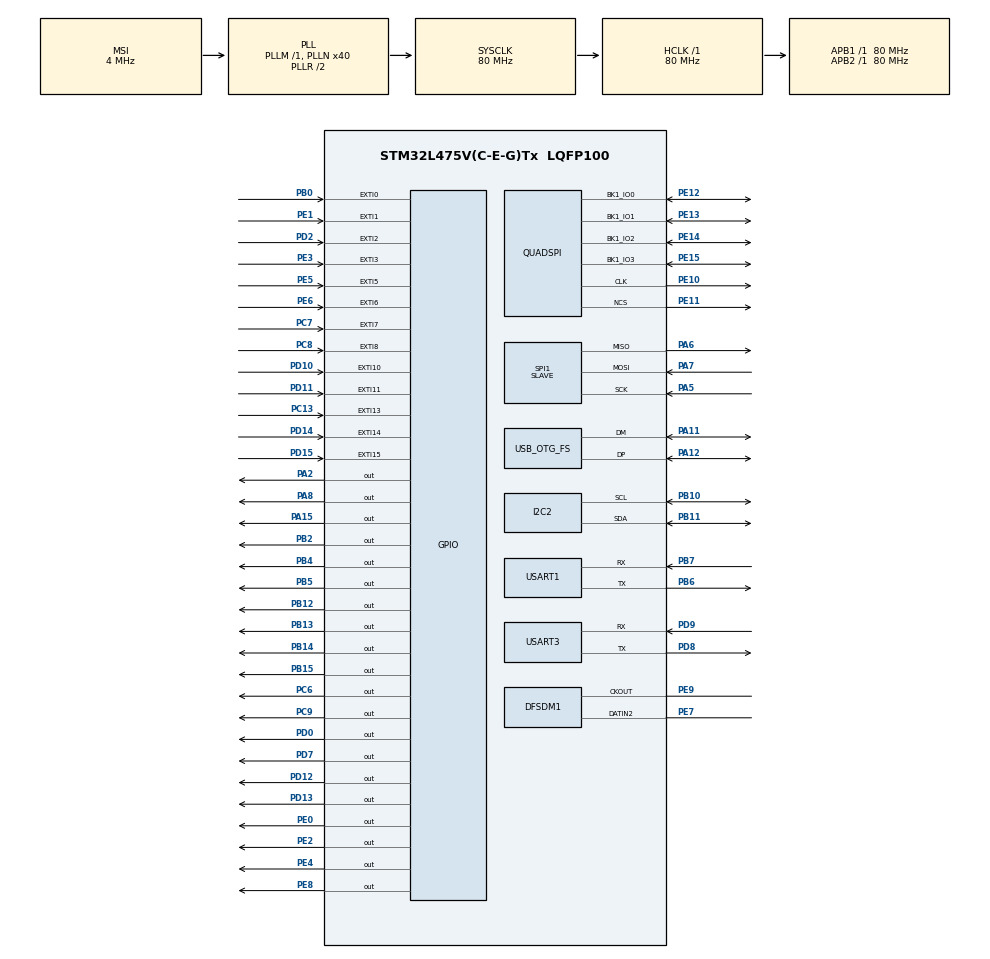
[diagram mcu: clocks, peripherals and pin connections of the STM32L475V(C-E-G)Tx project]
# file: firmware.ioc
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FREERTOS.Tasks01=defaultTask,0,128,StartDefaultTask,Default,NULL
Mcu.Family=STM32L4
Mcu.Name=STM32L475V(C-E-G)Tx
Mcu.Package=LQFP100
NVIC.EXTI15_10_IRQn=true\:5\:0\:false\:false\:true\:true\:true
NVIC.EXTI9_5_IRQn=true\:5\:0\:false\:false\:true\:true\:true
NVIC.PriorityGroup=NVIC_PRIORITYGROUP_4
NVIC.SPI1_IRQn=true\:5\:0\:false\:false\:true\:true\:true
NVIC.TIM1_UP_TIM16_IRQn=true\:0\:0\:false\:false\:true\:false\:false
NVIC.TimeBase=TIM1_UP_TIM16_IRQn
NVIC.TimeBaseIP=TIM1
PA0.GPIO_ModeDefaultPP=GPIO_MODE_AF_PP
PA0.GPIO_PuPd=GPIO_NOPULL
PA0.GPIO_Speed=GPIO_SPEED_FREQ_VERY_HIGH
PA0.Signal=UART4_TX
PA1.GPIO_ModeDefaultPP=GPIO_MODE_AF_PP
PA1.GPIO_PuPd=GPIO_NOPULL
PA1.GPIO_Speed=GPIO_SPEED_FREQ_VERY_HIGH
PA1.Signal=UART4_RX
PA10.GPIO_Mode=GPIO_MODE_AF_PP
PA10.GPIO_PuPd=GPIO_NOPULL
PA10.GPIO_Speed=GPIO_SPEED_FREQ_VERY_HIGH
PA10.Signal=USB_OTG_FS_ID
PA11.GPIO_Mode=GPIO_MODE_AF_PP
PA11.GPIO_PuPd=GPIO_NOPULL
PA11.GPIO_Speed=GPIO_SPEED_FREQ_VERY_HIGH
PA11.Mode=Device_Only
PA11.Signal=USB_OTG_FS_DM
PA12.GPIO_Mode=GPIO_MODE_AF_PP
PA12.GPIO_PuPd=GPIO_NOPULL
PA12.GPIO_Speed=GPIO_SPEED_FREQ_VERY_HIGH
PA12.Mode=Device_Only
PA12.Signal=USB_OTG_FS_DP
PA13\ (JTMS-SWDIO).Mode=Serial_Wire
PA13\ (JTMS-SWDIO).Signal=SYS_JTMS-SWDIO
PA14\ (JTCK-SWCLK).Mode=Serial_Wire
PA14\ (JTCK-SWCLK).Signal=SYS_JTCK-SWCLK
PA15\ (JTDI).GPIO_ModeDefaultOutputPP=GPIO_MODE_OUTPUT_PP
PA15\ (JTDI).GPIO_PuPd=GPIO_NOPULL
PA15\ (JTDI).GPIO_Speed=GPIO_SPEED_FREQ_LOW
PA15\ (JTDI).PinState=GPIO_PIN_RESET
PA15\ (JTDI).Signal=GPIO_Output
PA2.GPIO_ModeDefaultOutputPP=GPIO_MODE_OUTPUT_PP
PA2.GPIO_PuPd=GPIO_NOPULL
PA2.GPIO_Speed=GPIO_SPEED_FREQ_LOW
PA2.PinState=GPIO_PIN_RESET
PA2.Signal=GPIO_Output
PA3.GPIO_ModeDefaultPP=GPIO_MODE_AF_PP
PA3.GPIO_PuPd=GPIO_NOPULL
PA3.GPIO_Speed=GPIO_SPEED_FREQ_LOW
PA3.Signal=S_TIM2_CH4
PA4.GPIO_Mode=GPIO_MODE_ANALOG_ADC_CONTROL
PA4.GPIO_PuPd=GPIO_NOPULL
PA4.Signal=ADCx_IN9
PA5.GPIO_Mode=GPIO_MODE_AF_PP
PA5.GPIO_PuPd=GPIO_NOPULL
PA5.GPIO_Speed=GPIO_SPEED_FREQ_VERY_HIGH
PA5.Mode=Full_Duplex_Slave
PA5.Signal=SPI1_SCK
PA6.GPIO_Mode=GPIO_MODE_AF_PP
PA6.GPIO_PuPd=GPIO_NOPULL
PA6.GPIO_Speed=GPIO_SPEED_FREQ_VERY_HIGH
PA6.Mode=Full_Duplex_Slave
PA6.Signal=SPI1_MISO
PA7.GPIO_Mode=GPIO_MODE_AF_PP
PA7.GPIO_PuPd=GPIO_NOPULL
PA7.GPIO_Speed=GPIO_SPEED_FREQ_VERY_HIGH
PA7.Mode=Full_Duplex_Slave
PA7.Signal=SPI1_MOSI
PA8.GPIO_ModeDefaultOutputPP=GPIO_MODE_OUTPUT_PP
PA8.GPIO_PuPd=GPIO_NOPULL
PA8.GPIO_Speed=GPIO_SPEED_FREQ_LOW
PA8.PinState=GPIO_PIN_RESET
PA8.Signal=GPIO_Output
PA9.GPIO_Mode=GPIO_MODE_INPUT
PA9.GPIO_PuPd=GPIO_NOPULL
PA9.Signal=USB_OTG_FS_VBUS
PB0.GPIO_ModeDefaultEXTI=GPIO_MODE_IT_RISING
PB0.GPIO_PuPd=GPIO_NOPULL
PB0.Signal=GPXTI0
PB1.GPIO_Mode=GPIO_MODE_ANALOG_ADC_CONTROL
PB1.GPIO_PuPd=GPIO_NOPULL
PB1.Signal=ADCx_IN16
PB10.GPIO_Mode=GPIO_MODE_AF_OD
PB10.GPIO_PuPdOD=GPIO_PULLUP
PB10.GPIO_Speed=GPIO_SPEED_FREQ_VERY_HIGH
PB10.Mode=I2C
PB10.Signal=I2C2_SCL
PB11.GPIO_Mode=GPIO_MODE_AF_OD
PB11.GPIO_PuPdOD=GPIO_PULLUP
PB11.GPIO_Speed=GPIO_SPEED_FREQ_VERY_HIGH
PB11.Mode=I2C
PB11.Signal=I2C2_SDA
PB12.GPIO_ModeDefaultOutputPP=GPIO_MODE_OUTPUT_PP
PB12.GPIO_PuPd=GPIO_NOPULL
PB12.GPIO_Speed=GPIO_SPEED_FREQ_LOW
PB12.PinState=GPIO_PIN_RESET
PB12.Signal=GPIO_Output
PB13.GPIO_ModeDefaultOutputPP=GPIO_MODE_OUTPUT_PP
PB13.GPIO_PuPd=GPIO_NOPULL
PB13.GPIO_Speed=GPIO_SPEED_FREQ_LOW
PB13.PinState=GPIO_PIN_RESET
PB13.Signal=GPIO_Output
PB14.GPIO_ModeDefaultOutputPP=GPIO_MODE_OUTPUT_PP
PB14.GPIO_PuPd=GPIO_NOPULL
PB14.GPIO_Speed=GPIO_SPEED_FREQ_LOW
PB14.PinState=GPIO_PIN_RESET
PB14.Signal=GPIO_Output
PB15.GPIO_ModeDefaultOutputPP=GPIO_MODE_OUTPUT_PP
PB15.GPIO_PuPd=GPIO_NOPULL
PB15.GPIO_Speed=GPIO_SPEED_FREQ_LOW
PB15.PinState=GPIO_PIN_RESET
PB15.Signal=GPIO_Output
PB2.GPIO_ModeDefaultOutputPP=GPIO_MODE_OUTPUT_PP
PB2.GPIO_PuPd=GPIO_NOPULL
PB2.GPIO_Speed=GPIO_SPEED_FREQ_LOW
PB2.PinState=GPIO_PIN_RESET
PB2.Signal=GPIO_Output
PB3\ (JTDO-TRACESWO).Signal=SYS_JTDO-SWO
PB4\ (NJTRST).GPIO_ModeDefaultOutputPP=GPIO_MODE_OUTPUT_PP
PB4\ (NJTRST).GPIO_PuPd=GPIO_NOPULL
PB4\ (NJTRST).GPIO_Speed=GPIO_SPEED_FREQ_LOW
PB4\ (NJTRST).PinState=GPIO_PIN_RESET
PB4\ (NJTRST).Signal=GPIO_Output
PB5.GPIO_ModeDefaultOutputPP=GPIO_MODE_OUTPUT_PP
PB5.GPIO_PuPd=GPIO_NOPULL
PB5.GPIO_Speed=GPIO_SPEED_FREQ_LOW
PB5.PinState=GPIO_PIN_RESET
PB5.Signal=GPIO_Output
PB6.GPIO_FM6=__NULL
PB6.GPIO_ModeDefaultPP=GPIO_MODE_AF_PP
PB6.GPIO_PuPd=GPIO_NOPULL
PB6.GPIO_Speed=GPIO_SPEED_FREQ_VERY_HIGH
PB6.Mode=Asynchronous
PB6.Signal=USART1_TX
PB7.GPIO_FM7=__NULL
PB7.GPIO_ModeDefaultPP=GPIO_MODE_AF_PP
PB7.GPIO_PuPd=GPIO_NOPULL
PB7.GPIO_Speed=GPIO_SPEED_FREQ_VERY_HIGH
PB7.Mode=Asynchronous
PB7.Signal=USART1_RX
PB8.GPIO_FM8=__NULL
PB8.GPIO_Mode=GPIO_MODE_AF_OD
PB8.GPIO_PuPdOD=GPIO_PULLUP
PB8.GPIO_Speed=GPIO_SPEED_FREQ_VERY_HIGH
PB8.Signal=I2C1_SCL
PB9.GPIO_FM9=__NULL
PB9.GPIO_Mode=GPIO_MODE_AF_OD
PB9.GPIO_PuPdOD=GPIO_PULLUP
PB9.GPIO_Speed=GPIO_SPEED_FREQ_VERY_HIGH
PB9.Signal=I2C1_SDA
PC0.GPIO_Mode=GPIO_MODE_ANALOG_ADC_CONTROL
PC0.GPIO_PuPd=GPIO_NOPULL
PC0.Signal=ADCx_IN1
PC1.GPIO_Mode=GPIO_MODE_ANALOG_ADC_CONTROL
PC1.GPIO_PuPd=GPIO_NOPULL
PC1.Signal=ADCx_IN2
PC10.GPIO_Mode=GPIO_MODE_AF_PP
PC10.GPIO_PuPd=GPIO_NOPULL
PC10.GPIO_Speed=GPIO_SPEED_FREQ_VERY_HIGH
PC10.Signal=SPI3_SCK
PC11.GPIO_Mode=GPIO_MODE_AF_PP
PC11.GPIO_PuPd=GPIO_NOPULL
PC11.GPIO_Speed=GPIO_SPEED_FREQ_VERY_HIGH
PC11.Signal=SPI3_MISO
PC12.GPIO_Mode=GPIO_MODE_AF_PP
PC12.GPIO_PuPd=GPIO_NOPULL
PC12.GPIO_Speed=GPIO_SPEED_FREQ_VERY_HIGH
PC12.Signal=SPI3_MOSI
PC13.GPIO_ModeDefaultEXTI=GPIO_MODE_IT_RISING
PC13.GPIO_PuPd=GPIO_NOPULL
PC13.Signal=GPXTI13
PC14-OSC32_IN\ (PC14).Mode=LSE-External-Oscillator
PC14-OSC32_IN\ (PC14).Signal=RCC_OSC32_IN
PC15-OSC32_OUT\ (PC15).Mode=LSE-External-Oscillator
PC15-OSC32_OUT\ (PC15).Signal=RCC_OSC32_OUT
PC2.GPIO_Mode=GPIO_MODE_ANALOG_ADC_CONTROL
PC2.GPIO_PuPd=GPIO_NOPULL
PC2.Signal=ADCx_IN3
PC3.GPIO_Mode=GPIO_MODE_ANALOG_ADC_CONTROL
PC3.GPIO_PuPd=GPIO_NOPULL
PC3.Signal=ADCx_IN4
PC4.GPIO_Mode=GPIO_MODE_ANALOG_ADC_CONTROL
PC4.GPIO_PuPd=GPIO_NOPULL
PC4.Signal=ADCx_IN13
PC5.GPIO_Mode=GPIO_MODE_ANALOG_ADC_CONTROL
PC5.GPIO_PuPd=GPIO_NOPULL
PC5.Signal=ADCx_IN14
PC6.GPIO_ModeDefaultOutputPP=GPIO_MODE_OUTPUT_PP
PC6.GPIO_PuPd=GPIO_NOPULL
PC6.GPIO_Speed=GPIO_SPEED_FREQ_LOW
PC6.PinState=GPIO_PIN_RESET
PC6.Signal=GPIO_Output
PC7.GPIO_ModeDefaultEXTI=GPIO_MODE_IT_RISING
PC7.GPIO_PuPd=GPIO_NOPULL
PC7.Signal=GPXTI7
PC8.GPIO_ModeDefaultEXTI=GPIO_MODE_IT_RISING
PC8.GPIO_PuPd=GPIO_NOPULL
PC8.Signal=GPXTI8
PC9.GPIO_ModeDefaultOutputPP=GPIO_MODE_OUTPUT_PP
PC9.GPIO_PuPd=GPIO_NOPULL
PC9.GPIO_Speed=GPIO_SPEED_FREQ_LOW
PC9.PinState=GPIO_PIN_RESET
PC9.Signal=GPIO_Output
PD0.GPIO_ModeDefaultOutputPP=GPIO_MODE_OUTPUT_PP
PD0.GPIO_PuPd=GPIO_NOPULL
PD0.GPIO_Speed=GPIO_SPEED_FREQ_LOW
PD0.PinState=GPIO_PIN_RESET
PD0.Signal=GPIO_Output
PD1.GPIO_Mode=GPIO_MODE_AF_PP
PD1.GPIO_PuPd=GPIO_NOPULL
PD1.GPIO_Speed=GPIO_SPEED_FREQ_VERY_HIGH
PD1.Signal=SPI2_SCK
PD10.GPIO_ModeDefaultEXTI=GPIO_MODE_IT_RISING
PD10.GPIO_PuPd=GPIO_NOPULL
PD10.Signal=GPXTI10
PD11.GPIO_ModeDefaultEXTI=GPIO_MODE_IT_RISING
PD11.GPIO_PuPd=GPIO_NOPULL
PD11.Signal=GPXTI11
PD12.GPIO_ModeDefaultOutputPP=GPIO_MODE_OUTPUT_PP
PD12.GPIO_PuPd=GPIO_NOPULL
PD12.GPIO_Speed=GPIO_SPEED_FREQ_LOW
PD12.PinState=GPIO_PIN_RESET
PD12.Signal=GPIO_Output
PD13.GPIO_ModeDefaultOutputPP=GPIO_MODE_OUTPUT_PP
PD13.GPIO_PuPd=GPIO_NOPULL
PD13.GPIO_Speed=GPIO_SPEED_FREQ_LOW
PD13.PinState=GPIO_PIN_RESET
PD13.Signal=GPIO_Output
PD14.GPIO_ModeDefaultEXTI=GPIO_MODE_IT_RISING
PD14.GPIO_PuPd=GPIO_NOPULL
PD14.Signal=GPXTI14
PD15.GPIO_ModeDefaultEXTI=GPIO_MODE_IT_RISING
PD15.GPIO_PuPd=GPIO_NOPULL
PD15.Signal=GPXTI15
PD2.GPIO_ModeDefaultEXTI=GPIO_MODE_IT_RISING
PD2.GPIO_PuPd=GPIO_NOPULL
PD2.Signal=GPXTI2
PD3.GPIO_Mode=GPIO_MODE_AF_PP
PD3.GPIO_PuPd=GPIO_NOPULL
PD3.GPIO_Speed=GPIO_SPEED_FREQ_VERY_HIGH
PD3.Signal=USART2_CTS
PD4.GPIO_Mode=GPIO_MODE_AF_PP
PD4.GPIO_PuPd=GPIO_NOPULL
PD4.GPIO_Speed=GPIO_SPEED_FREQ_VERY_HIGH
PD4.Signal=USART2_RTS
PD5.GPIO_ModeDefaultPP=GPIO_MODE_AF_PP
PD5.GPIO_PuPd=GPIO_NOPULL
PD5.GPIO_Speed=GPIO_SPEED_FREQ_VERY_HIGH
PD5.Signal=USART2_TX
PD6.GPIO_ModeDefaultPP=GPIO_MODE_AF_PP
PD6.GPIO_PuPd=GPIO_NOPULL
PD6.GPIO_Speed=GPIO_SPEED_FREQ_VERY_HIGH
PD6.Signal=USART2_RX
PD7.GPIO_ModeDefaultOutputPP=GPIO_MODE_OUTPUT_PP
PD7.GPIO_PuPd=GPIO_NOPULL
PD7.GPIO_Speed=GPIO_SPEED_FREQ_LOW
PD7.PinState=GPIO_PIN_RESET
PD7.Signal=GPIO_Output
PD8.GPIO_ModeDefaultPP=GPIO_MODE_AF_PP
PD8.GPIO_PuPd=GPIO_NOPULL
PD8.GPIO_Speed=GPIO_SPEED_FREQ_VERY_HIGH
PD8.Mode=Asynchronous
PD8.Signal=USART3_TX
PD9.GPIO_ModeDefaultPP=GPIO_MODE_AF_PP
PD9.GPIO_PuPd=GPIO_NOPULL
PD9.GPIO_Speed=GPIO_SPEED_FREQ_VERY_HIGH
PD9.Mode=Asynchronous
PD9.Signal=USART3_RX
PE0.GPIO_ModeDefaultOutputPP=GPIO_MODE_OUTPUT_PP
PE0.GPIO_PuPd=GPIO_NOPULL
PE0.GPIO_Speed=GPIO_SPEED_FREQ_LOW
PE0.PinState=GPIO_PIN_RESET
PE0.Signal=GPIO_Output
PE1.GPIO_ModeDefaultEXTI=GPIO_MODE_IT_RISING
PE1.GPIO_PuPd=GPIO_NOPULL
PE1.Signal=GPXTI1
PE10.GPIO_Mode=GPIO_MODE_AF_PP
PE10.GPIO_PuPd=GPIO_NOPULL
PE10.GPIO_Speed=GPIO_SPEED_FREQ_VERY_HIGH
PE10.Mode=Single Bank
PE10.Signal=QUADSPI_CLK
PE11.GPIO_Mode=GPIO_MODE_AF_PP
PE11.GPIO_PuPd=GPIO_NOPULL
PE11.GPIO_Speed=GPIO_SPEED_FREQ_VERY_HIGH
PE11.Mode=Single Bank
PE11.Signal=QUADSPI_NCS
PE12.GPIO_Mode=GPIO_MODE_AF_PP
PE12.GPIO_PuPd=GPIO_NOPULL
PE12.GPIO_Speed=GPIO_SPEED_FREQ_VERY_HIGH
PE12.Mode=Single Bank
PE12.Signal=QUADSPI_BK1_IO0
PE13.GPIO_Mode=GPIO_MODE_AF_PP
PE13.GPIO_PuPd=GPIO_NOPULL
PE13.GPIO_Speed=GPIO_SPEED_FREQ_VERY_HIGH
PE13.Mode=Single Bank
PE13.Signal=QUADSPI_BK1_IO1
PE14.GPIO_Mode=GPIO_MODE_AF_PP
PE14.GPIO_PuPd=GPIO_NOPULL
PE14.GPIO_Speed=GPIO_SPEED_FREQ_VERY_HIGH
PE14.Mode=Single Bank
PE14.Signal=QUADSPI_BK1_IO2
PE15.GPIO_Mode=GPIO_MODE_AF_PP
PE15.GPIO_PuPd=GPIO_NOPULL
PE15.GPIO_Speed=GPIO_SPEED_FREQ_VERY_HIGH
PE15.Mode=Single Bank
PE15.Signal=QUADSPI_BK1_IO3
PE2.GPIO_ModeDefaultOutputPP=GPIO_MODE_OUTPUT_PP
PE2.GPIO_PuPd=GPIO_NOPULL
PE2.GPIO_Speed=GPIO_SPEED_FREQ_LOW
PE2.PinState=GPIO_PIN_RESET
PE2.Signal=GPIO_Output
PE3.GPIO_ModeDefaultEXTI=GPIO_MODE_IT_RISING
PE3.GPIO_PuPd=GPIO_NOPULL
PE3.Signal=GPXTI3
PE4.GPIO_ModeDefaultOutputPP=GPIO_MODE_OUTPUT_PP
PE4.GPIO_PuPd=GPIO_NOPULL
PE4.GPIO_Speed=GPIO_SPEED_FREQ_LOW
PE4.PinState=GPIO_PIN_RESET
PE4.Signal=GPIO_Output
PE5.GPIO_ModeDefaultEXTI=GPIO_MODE_IT_RISING
PE5.GPIO_PuPd=GPIO_NOPULL
PE5.Signal=GPXTI5
PE6.GPIO_ModeDefaultEXTI=GPIO_MODE_IT_RISING
PE6.GPIO_PuPd=GPIO_NOPULL
PE6.Signal=GPXTI6
PE7.GPIO_Mode=GPIO_MODE_AF_PP
PE7.GPIO_PuPd=GPIO_NOPULL
PE7.GPIO_Speed=GPIO_SPEED_FREQ_LOW
PE7.Signal=S_DATAIN2DFSDM1
PE8.GPIO_ModeDefaultOutputPP=GPIO_MODE_OUTPUT_PP
PE8.GPIO_PuPd=GPIO_NOPULL
PE8.GPIO_Speed=GPIO_SPEED_FREQ_LOW
PE8.PinState=GPIO_PIN_RESET
PE8.Signal=GPIO_Output
PE9.GPIO_Mode=GPIO_MODE_AF_PP
PE9.GPIO_PuPd=GPIO_NOPULL
PE9.GPIO_Speed=GPIO_SPEED_FREQ_LOW
PE9.Signal=S_CKOUTDFSDM1
ProjectManager.HeapSize=0x200
ProjectManager.StackSize=0x400
ProjectManager.TargetToolchain=Makefile
RCC.ADCFreq_Value=48000000
RCC.AHBFreq_Value=80000000
RCC.APB1Freq_Value=80000000
RCC.APB1TimFreq_Value=80000000
RCC.APB2Freq_Value=80000000
RCC.APB2TimFreq_Value=80000000
RCC.CortexFreq_Value=80000000
RCC.HCLKFreq_Value=80000000
RCC.HSE_VALUE=8000000
RCC.HSI_VALUE=16000000
RCC.MSI_VALUE=4000000
RCC.PLLN=40
RCC.PLLSAI1N=24
RCC.SYSCLKFreq_VALUE=80000000
RCC.SYSCLKSource=RCC_SYSCLKSOURCE_PLLCLK
RCC.USBFreq_Value=48000000
RCC.VCOOutputFreq_Value=160000000
SH.ADCx_IN1.0=ADC1_IN1
SH.ADCx_IN13.0=ADC1_IN13
SH.ADCx_IN14.0=ADC1_IN14
SH.ADCx_IN16.0=ADC1_IN16
SH.ADCx_IN2.0=ADC1_IN2
SH.ADCx_IN3.0=ADC1_IN3
SH.ADCx_IN4.0=ADC1_IN4
SH.ADCx_IN9.0=ADC1_IN9
SH.S_CKOUTDFSDM1.0=DFSDM1_CKOUT,CKOUT
SH.S_CKOUTDFSDM1.1=DFSDM1_CKOUT,PDM_SPI_Input_from_ch12_and_Internal_Clock
SH.S_DATAIN2DFSDM1.0=DFSDM1_DATIN2,PDM_SPI_Input_from_ch12_and_Internal_Clock
SH.S_TIM2_CH4.0=TIM2_CH4
SPI1.DataSize=SPI_DATASIZE_8BIT
SPI1.Direction=SPI_DIRECTION_2LINES
SPI1.Mode=SPI_MODE_SLAVE
SPI1.VirtualType=VM_SLAVE
USART1.VirtualMode-Asynchronous=VM_ASYNC
USART3.VirtualMode-Asynchronous=VM_ASYNC
USB_OTG_FS.VirtualMode=Device_Only
VP_FREERTOS_VS_ENABLE.Mode=Enabled
VP_SYS_VS_tim1.Mode=TIM1
board=B-L475E-IOT01A

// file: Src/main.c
/* USER CODE BEGIN Header */
/**
  ******************************************************************************
  * @file           : main.c
  * @brief          : Main program body
  ******************************************************************************
  * This notice applies to any and all portions of this file
  * that are not between comment pairs USER CODE BEGIN and
  * USER CODE END. Other portions of this file, whether
  * inserted by the user or by software development tools
  * are owned by their respective copyright owners.
  *
  * Copyright (c) 2019 STMicroelectronics International N.V.
  * All rights reserved.
  *
  * Redistribution and use in source and binary forms, with or without
  * modification, are permitted, provided that the following conditions are met:
  *
  * 1. Redistribution of source code must retain the above copyright notice,
  *    this list of conditions and the following disclaimer.
  * 2. Redistributions in binary form must reproduce the above copyright notice,
  *    this list of conditions and the following disclaimer in the documentation
  *    and/or other materials provided with the distribution.
  * 3. Neither the name of STMicroelectronics nor the names of other
  *    contributors to this software may be used to endorse or promote products
  *    derived from this software without specific written permission.
  * 4. This software, including modifications and/or derivative works of this
  *    software, must execute solely and exclusively on microcontroller or
  *    microprocessor devices manufactured by or for STMicroelectronics.
  * 5. Redistribution and use of this software other than as permitted under
  *    this license is void and will automatically terminate your rights under
  *    this license.
  *
  * THIS SOFTWARE IS PROVIDED BY STMICROELECTRONICS AND CONTRIBUTORS "AS IS"
  * AND ANY EXPRESS, IMPLIED OR STATUTORY WARRANTIES, INCLUDING, BUT NOT
  * LIMITED TO, THE IMPLIED WARRANTIES OF MERCHANTABILITY, FITNESS FOR A
  * PARTICULAR PURPOSE AND NON-INFRINGEMENT OF THIRD PARTY INTELLECTUAL PROPERTY
  * RIGHTS ARE DISCLAIMED TO THE FULLEST EXTENT PERMITTED BY LAW. IN NO EVENT
  * SHALL STMICROELECTRONICS OR CONTRIBUTORS BE LIABLE FOR ANY DIRECT, INDIRECT,
  * INCIDENTAL, SPECIAL, EXEMPLARY, OR CONSEQUENTIAL DAMAGES (INCLUDING, BUT NOT
  * LIMITED TO, PROCUREMENT OF SUBSTITUTE GOODS OR SERVICES; LOSS OF USE, DATA,
  * OR PROFITS; OR BUSINESS INTERRUPTION) HOWEVER CAUSED AND ON ANY THEORY OF
  * LIABILITY, WHETHER IN CONTRACT, STRICT LIABILITY, OR TORT (INCLUDING
  * NEGLIGENCE OR OTHERWISE) ARISING IN ANY WAY OUT OF THE USE OF THIS SOFTWARE,
  * EVEN IF ADVISED OF THE POSSIBILITY OF SUCH DAMAGE.
  *
  ******************************************************************************
  */
/* USER CODE END Header */

#include "main.h"
#include "cmsis_os.h"

/* USER CODE BEGIN Includes */
#include "SEGGER_RTT.h"
#include "spi.h"

/* USER CODE END Includes */

DFSDM_Channel_HandleTypeDef hdfsdm1_channel1;

I2C_HandleTypeDef hi2c2;

QSPI_HandleTypeDef hqspi;

SPI_HandleTypeDef hspi1;

UART_HandleTypeDef huart1;
UART_HandleTypeDef huart3;

PCD_HandleTypeDef hpcd_USB_OTG_FS;

osThreadId defaultTaskHandle;

void SystemClock_Config(void);
static void MX_GPIO_Init(void);
static void MX_DFSDM1_Init(void);
static void MX_I2C2_Init(void);
static void MX_QUADSPI_Init(void);
static void MX_USART1_UART_Init(void);
static void MX_USART3_UART_Init(void);
static void MX_USB_OTG_FS_PCD_Init(void);
static void MX_SPI1_Init(void);
void StartDefaultTask(void const * argument);

int main(void)
{

  /* MCU Configuration--------------------------------------------------------*/

  /* Reset of all peripherals, Initializes the Flash interface and the Systick. */
  HAL_Init();

  /* Configure the system clock */
  SystemClock_Config();

  /* Initialize all configured peripherals */
  MX_GPIO_Init();
  MX_DFSDM1_Init();
  MX_I2C2_Init();
  MX_QUADSPI_Init();
  MX_USART1_UART_Init();
  MX_USART3_UART_Init();
  MX_USB_OTG_FS_PCD_Init();
  MX_SPI1_Init();

  /* Create the thread(s) */
  /* definition and creation of defaultTask */
  osThreadDef(defaultTask, StartDefaultTask, osPriorityNormal, 0, 128);
  defaultTaskHandle = osThreadCreate(osThread(defaultTask), NULL);

  /* Start scheduler */
  osKernelStart();

  /* We should never get here as control is now taken by the scheduler */

  /* Infinite loop */
  while (1)
  {

  }
}

void SystemClock_Config(void)
{
  RCC_OscInitTypeDef RCC_OscInitStruct = {0};
  RCC_ClkInitTypeDef RCC_ClkInitStruct = {0};
  RCC_PeriphCLKInitTypeDef PeriphClkInit = {0};

  /**Configure LSE Drive Capability
  */
  HAL_PWR_EnableBkUpAccess();
  __HAL_RCC_LSEDRIVE_CONFIG(RCC_LSEDRIVE_LOW);
  /**Initializes the CPU, AHB and APB busses clocks
  */
  RCC_OscInitStruct.OscillatorType = RCC_OSCILLATORTYPE_LSE|RCC_OSCILLATORTYPE_MSI;
  RCC_OscInitStruct.LSEState = RCC_LSE_ON;
  RCC_OscInitStruct.MSIState = RCC_MSI_ON;
  RCC_OscInitStruct.MSICalibrationValue = 0;
  RCC_OscInitStruct.MSIClockRange = RCC_MSIRANGE_6;
  RCC_OscInitStruct.PLL.PLLState = RCC_PLL_ON;
  RCC_OscInitStruct.PLL.PLLSource = RCC_PLLSOURCE_MSI;
  RCC_OscInitStruct.PLL.PLLM = 1;
  RCC_OscInitStruct.PLL.PLLN = 40;
  RCC_OscInitStruct.PLL.PLLP = RCC_PLLP_DIV7;
  RCC_OscInitStruct.PLL.PLLQ = RCC_PLLQ_DIV2;
  RCC_OscInitStruct.PLL.PLLR = RCC_PLLR_DIV2;
  if (HAL_RCC_OscConfig(&RCC_OscInitStruct) != HAL_OK)
  {
    Error_Handler();
  }
  /**Initializes the CPU, AHB and APB busses clocks
  */
  RCC_ClkInitStruct.ClockType = RCC_CLOCKTYPE_HCLK|RCC_CLOCKTYPE_SYSCLK
                              |RCC_CLOCKTYPE_PCLK1|RCC_CLOCKTYPE_PCLK2;
  RCC_ClkInitStruct.SYSCLKSource = RCC_SYSCLKSOURCE_PLLCLK;
  RCC_ClkInitStruct.AHBCLKDivider = RCC_SYSCLK_DIV1;
  RCC_ClkInitStruct.APB1CLKDivider = RCC_HCLK_DIV1;
  RCC_ClkInitStruct.APB2CLKDivider = RCC_HCLK_DIV1;

  if (HAL_RCC_ClockConfig(&RCC_ClkInitStruct, FLASH_LATENCY_4) != HAL_OK)
  {
    Error_Handler();
  }
  PeriphClkInit.PeriphClockSelection = RCC_PERIPHCLK_USART1|RCC_PERIPHCLK_USART3
                              |RCC_PERIPHCLK_I2C2|RCC_PERIPHCLK_DFSDM1
                              |RCC_PERIPHCLK_USB;
  PeriphClkInit.Usart1ClockSelection = RCC_USART1CLKSOURCE_PCLK2;
  PeriphClkInit.Usart3ClockSelection = RCC_USART3CLKSOURCE_PCLK1;
  PeriphClkInit.I2c2ClockSelection = RCC_I2C2CLKSOURCE_PCLK1;
  PeriphClkInit.Dfsdm1ClockSelection = RCC_DFSDM1CLKSOURCE_PCLK;
  PeriphClkInit.UsbClockSelection = RCC_USBCLKSOURCE_PLLSAI1;
  PeriphClkInit.PLLSAI1.PLLSAI1Source = RCC_PLLSOURCE_MSI;
  PeriphClkInit.PLLSAI1.PLLSAI1M = 1;
  PeriphClkInit.PLLSAI1.PLLSAI1N = 24;
  PeriphClkInit.PLLSAI1.PLLSAI1P = RCC_PLLP_DIV7;
  PeriphClkInit.PLLSAI1.PLLSAI1Q = RCC_PLLQ_DIV2;
  PeriphClkInit.PLLSAI1.PLLSAI1R = RCC_PLLR_DIV2;
  PeriphClkInit.PLLSAI1.PLLSAI1ClockOut = RCC_PLLSAI1_48M2CLK;
  if (HAL_RCCEx_PeriphCLKConfig(&PeriphClkInit) != HAL_OK)
  {
    Error_Handler();
  }
  /**Configure the main internal regulator output voltage
  */
  if (HAL_PWREx_ControlVoltageScaling(PWR_REGULATOR_VOLTAGE_SCALE1) != HAL_OK)
  {
    Error_Handler();
  }
  /**Enable MSI Auto calibration
  */
  HAL_RCCEx_EnableMSIPLLMode();
}

static void MX_DFSDM1_Init(void)
{

  hdfsdm1_channel1.Instance = DFSDM1_Channel1;
  hdfsdm1_channel1.Init.OutputClock.Activation = ENABLE;
  hdfsdm1_channel1.Init.OutputClock.Selection = DFSDM_CHANNEL_OUTPUT_CLOCK_SYSTEM;
  hdfsdm1_channel1.Init.OutputClock.Divider = 2;
  hdfsdm1_channel1.Init.Input.Multiplexer = DFSDM_CHANNEL_EXTERNAL_INPUTS;
  hdfsdm1_channel1.Init.Input.DataPacking = DFSDM_CHANNEL_STANDARD_MODE;
  hdfsdm1_channel1.Init.Input.Pins = DFSDM_CHANNEL_FOLLOWING_CHANNEL_PINS;
  hdfsdm1_channel1.Init.SerialInterface.Type = DFSDM_CHANNEL_SPI_RISING;
  hdfsdm1_channel1.Init.SerialInterface.SpiClock = DFSDM_CHANNEL_SPI_CLOCK_INTERNAL;
  hdfsdm1_channel1.Init.Awd.FilterOrder = DFSDM_CHANNEL_FASTSINC_ORDER;
  hdfsdm1_channel1.Init.Awd.Oversampling = 1;
  hdfsdm1_channel1.Init.Offset = 0;
  hdfsdm1_channel1.Init.RightBitShift = 0x00;
  if (HAL_DFSDM_ChannelInit(&hdfsdm1_channel1) != HAL_OK)
  {
    Error_Handler();
  }

}

static void MX_I2C2_Init(void)
{

  hi2c2.Instance = I2C2;
  hi2c2.Init.Timing = 0x10909CEC;
  hi2c2.Init.OwnAddress1 = 0;
  hi2c2.Init.AddressingMode = I2C_ADDRESSINGMODE_7BIT;
  hi2c2.Init.DualAddressMode = I2C_DUALADDRESS_DISABLE;
  hi2c2.Init.OwnAddress2 = 0;
  hi2c2.Init.OwnAddress2Masks = I2C_OA2_NOMASK;
  hi2c2.Init.GeneralCallMode = I2C_GENERALCALL_DISABLE;
  hi2c2.Init.NoStretchMode = I2C_NOSTRETCH_DISABLE;
  if (HAL_I2C_Init(&hi2c2) != HAL_OK)
  {
    Error_Handler();
  }
  /**Configure Analogue filter
  */
  if (HAL_I2CEx_ConfigAnalogFilter(&hi2c2, I2C_ANALOGFILTER_ENABLE) != HAL_OK)
  {
    Error_Handler();
  }
  /**Configure Digital filter
  */
  if (HAL_I2CEx_ConfigDigitalFilter(&hi2c2, 0) != HAL_OK)
  {
    Error_Handler();
  }

}

static void MX_QUADSPI_Init(void)
{

  /* QUADSPI parameter configuration*/
  hqspi.Instance = QUADSPI;
  hqspi.Init.ClockPrescaler = 255;
  hqspi.Init.FifoThreshold = 1;
  hqspi.Init.SampleShifting = QSPI_SAMPLE_SHIFTING_NONE;
  hqspi.Init.FlashSize = 1;
  hqspi.Init.ChipSelectHighTime = QSPI_CS_HIGH_TIME_1_CYCLE;
  hqspi.Init.ClockMode = QSPI_CLOCK_MODE_0;
  if (HAL_QSPI_Init(&hqspi) != HAL_OK)
  {
    Error_Handler();
  }

}

static void MX_SPI1_Init(void)
{

  /* SPI1 parameter configuration*/
  hspi1.Instance = SPI1;
  hspi1.Init.Mode = SPI_MODE_SLAVE;
  hspi1.Init.Direction = SPI_DIRECTION_2LINES;
  hspi1.Init.DataSize = SPI_DATASIZE_8BIT;
  hspi1.Init.CLKPolarity = SPI_POLARITY_LOW;
  hspi1.Init.CLKPhase = SPI_PHASE_1EDGE;
  hspi1.Init.NSS = SPI_NSS_HARD_INPUT;
  hspi1.Init.FirstBit = SPI_FIRSTBIT_MSB;
  hspi1.Init.TIMode = SPI_TIMODE_DISABLE;
  hspi1.Init.CRCCalculation = SPI_CRCCALCULATION_DISABLE;
  hspi1.Init.CRCPolynomial = 7;
  hspi1.Init.CRCLength = SPI_CRC_LENGTH_DATASIZE;
  hspi1.Init.NSSPMode = SPI_NSS_PULSE_DISABLE;
  if (HAL_SPI_Init(&hspi1) != HAL_OK)
  {
    Error_Handler();
  }

}

static void MX_USART1_UART_Init(void)
{

  huart1.Instance = USART1;
  huart1.Init.BaudRate = 115200;
  huart1.Init.WordLength = UART_WORDLENGTH_8B;
  huart1.Init.StopBits = UART_STOPBITS_1;
  huart1.Init.Parity = UART_PARITY_NONE;
  huart1.Init.Mode = UART_MODE_TX_RX;
  huart1.Init.HwFlowCtl = UART_HWCONTROL_NONE;
  huart1.Init.OverSampling = UART_OVERSAMPLING_16;
  huart1.Init.OneBitSampling = UART_ONE_BIT_SAMPLE_DISABLE;
  huart1.AdvancedInit.AdvFeatureInit = UART_ADVFEATURE_NO_INIT;
  if (HAL_UART_Init(&huart1) != HAL_OK)
  {
    Error_Handler();
  }

}

static void MX_USART3_UART_Init(void)
{

  huart3.Instance = USART3;
  huart3.Init.BaudRate = 115200;
  huart3.Init.WordLength = UART_WORDLENGTH_8B;
  huart3.Init.StopBits = UART_STOPBITS_1;
  huart3.Init.Parity = UART_PARITY_NONE;
  huart3.Init.Mode = UART_MODE_TX_RX;
  huart3.Init.HwFlowCtl = UART_HWCONTROL_NONE;
  huart3.Init.OverSampling = UART_OVERSAMPLING_16;
  huart3.Init.OneBitSampling = UART_ONE_BIT_SAMPLE_DISABLE;
  huart3.AdvancedInit.AdvFeatureInit = UART_ADVFEATURE_NO_INIT;
  if (HAL_UART_Init(&huart3) != HAL_OK)
  {
    Error_Handler();
  }

}

static void MX_USB_OTG_FS_PCD_Init(void)
{

  hpcd_USB_OTG_FS.Instance = USB_OTG_FS;
  hpcd_USB_OTG_FS.Init.dev_endpoints = 6;
  hpcd_USB_OTG_FS.Init.speed = PCD_SPEED_FULL;
  hpcd_USB_OTG_FS.Init.ep0_mps = DEP0CTL_MPS_64;
  hpcd_USB_OTG_FS.Init.phy_itface = PCD_PHY_EMBEDDED;
  hpcd_USB_OTG_FS.Init.Sof_enable = DISABLE;
  hpcd_USB_OTG_FS.Init.low_power_enable = DISABLE;
  hpcd_USB_OTG_FS.Init.lpm_enable = DISABLE;
  hpcd_USB_OTG_FS.Init.battery_charging_enable = DISABLE;
  hpcd_USB_OTG_FS.Init.use_dedicated_ep1 = DISABLE;
  hpcd_USB_OTG_FS.Init.vbus_sensing_enable = DISABLE;
  if (HAL_PCD_Init(&hpcd_USB_OTG_FS) != HAL_OK)
  {
    Error_Handler();
  }

}

static void MX_GPIO_Init(void)
{
  GPIO_InitTypeDef GPIO_InitStruct = {0};

  /* GPIO Ports Clock Enable */
  __HAL_RCC_GPIOE_CLK_ENABLE();
  __HAL_RCC_GPIOC_CLK_ENABLE();
  __HAL_RCC_GPIOA_CLK_ENABLE();
  __HAL_RCC_GPIOB_CLK_ENABLE();
  __HAL_RCC_GPIOD_CLK_ENABLE();

  /*Configure GPIO pin Output Level */
  HAL_GPIO_WritePin(GPIOE, GPIO_PIN_2|GPIO_PIN_4|GPIO_PIN_8|GPIO_PIN_0, GPIO_PIN_RESET);

  /*Configure GPIO pin Output Level */
  HAL_GPIO_WritePin(GPIOA, GPIO_PIN_2|GPIO_PIN_8|GPIO_PIN_15, GPIO_PIN_RESET);

  /*Configure GPIO pin Output Level */
  HAL_GPIO_WritePin(GPIOB, GPIO_PIN_2|GPIO_PIN_12|GPIO_PIN_13|GPIO_PIN_14
                          |GPIO_PIN_15|GPIO_PIN_4|GPIO_PIN_5, GPIO_PIN_RESET);

  /*Configure GPIO pin Output Level */
  HAL_GPIO_WritePin(GPIOD, GPIO_PIN_12|GPIO_PIN_13|GPIO_PIN_0|GPIO_PIN_7, GPIO_PIN_RESET);

  /*Configure GPIO pin Output Level */
  HAL_GPIO_WritePin(GPIOC, GPIO_PIN_6|GPIO_PIN_9, GPIO_PIN_RESET);

  /*Configure GPIO pins : PE2 PE4 PE8 PE0 */
  GPIO_InitStruct.Pin = GPIO_PIN_2|GPIO_PIN_4|GPIO_PIN_8|GPIO_PIN_0;
  GPIO_InitStruct.Mode = GPIO_MODE_OUTPUT_PP;
  GPIO_InitStruct.Pull = GPIO_NOPULL;
  GPIO_InitStruct.Speed = GPIO_SPEED_FREQ_LOW;
  HAL_GPIO_Init(GPIOE, &GPIO_InitStruct);

  /*Configure GPIO pins : PE3 PE5 PE6 PE1 */
  GPIO_InitStruct.Pin = GPIO_PIN_3|GPIO_PIN_5|GPIO_PIN_6|GPIO_PIN_1;
  GPIO_InitStruct.Mode = GPIO_MODE_IT_RISING;
  GPIO_InitStruct.Pull = GPIO_NOPULL;
  HAL_GPIO_Init(GPIOE, &GPIO_InitStruct);

  /*Configure GPIO pins : PC13 PC7 PC8 */
  GPIO_InitStruct.Pin = GPIO_PIN_13|GPIO_PIN_7|GPIO_PIN_8;
  GPIO_InitStruct.Mode = GPIO_MODE_IT_RISING;
  GPIO_InitStruct.Pull = GPIO_NOPULL;
  HAL_GPIO_Init(GPIOC, &GPIO_InitStruct);

  /*Configure GPIO pins : PC0 PC1 PC2 PC3
                           PC4 PC5 */
  GPIO_InitStruct.Pin = GPIO_PIN_0|GPIO_PIN_1|GPIO_PIN_2|GPIO_PIN_3
                          |GPIO_PIN_4|GPIO_PIN_5;
  GPIO_InitStruct.Mode = GPIO_MODE_ANALOG_ADC_CONTROL;
  GPIO_InitStruct.Pull = GPIO_NOPULL;
  HAL_GPIO_Init(GPIOC, &GPIO_InitStruct);

  /*Configure GPIO pins : PA0 PA1 */
  GPIO_InitStruct.Pin = GPIO_PIN_0|GPIO_PIN_1;
  GPIO_InitStruct.Mode = GPIO_MODE_AF_PP;
  GPIO_InitStruct.Pull = GPIO_NOPULL;
  GPIO_InitStruct.Speed = GPIO_SPEED_FREQ_VERY_HIGH;
  GPIO_InitStruct.Alternate = GPIO_AF8_UART4;
  HAL_GPIO_Init(GPIOA, &GPIO_InitStruct);

  /*Configure GPIO pins : PA2 PA8 PA15 */
  GPIO_InitStruct.Pin = GPIO_PIN_2|GPIO_PIN_8|GPIO_PIN_15;
  GPIO_InitStruct.Mode = GPIO_MODE_OUTPUT_PP;
  GPIO_InitStruct.Pull = GPIO_NOPULL;
  GPIO_InitStruct.Speed = GPIO_SPEED_FREQ_LOW;
  HAL_GPIO_Init(GPIOA, &GPIO_InitStruct);

  /*Configure GPIO pin : PA3 */
  GPIO_InitStruct.Pin = GPIO_PIN_3;
  GPIO_InitStruct.Mode = GPIO_MODE_AF_PP;
  GPIO_InitStruct.Pull = GPIO_NOPULL;
  GPIO_InitStruct.Speed = GPIO_SPEED_FREQ_LOW;
  GPIO_InitStruct.Alternate = GPIO_AF1_TIM2;
  HAL_GPIO_Init(GPIOA, &GPIO_InitStruct);

  /*Configure GPIO pin : PA4 */
  GPIO_InitStruct.Pin = GPIO_PIN_4;
  GPIO_InitStruct.Mode = GPIO_MODE_AF_PP;
  GPIO_InitStruct.Pull = GPIO_NOPULL;
  GPIO_InitStruct.Speed = GPIO_SPEED_FREQ_VERY_HIGH;
  GPIO_InitStruct.Alternate = GPIO_AF5_SPI1;
  HAL_GPIO_Init(GPIOA, &GPIO_InitStruct);

  /*Configure GPIO pin : PB0 */
  GPIO_InitStruct.Pin = GPIO_PIN_0;
  GPIO_InitStruct.Mode = GPIO_MODE_IT_RISING;
  GPIO_InitStruct.Pull = GPIO_NOPULL;
  HAL_GPIO_Init(GPIOB, &GPIO_InitStruct);

  /*Configure GPIO pin : PB1 */
  GPIO_InitStruct.Pin = GPIO_PIN_1;
  GPIO_InitStruct.Mode = GPIO_MODE_ANALOG_ADC_CONTROL;
  GPIO_InitStruct.Pull = GPIO_NOPULL;
  HAL_GPIO_Init(GPIOB, &GPIO_InitStruct);

  /*Configure GPIO pins : PB2 PB12 PB13 PB14
                           PB15 PB4 PB5 */
  GPIO_InitStruct.Pin = GPIO_PIN_2|GPIO_PIN_12|GPIO_PIN_13|GPIO_PIN_14
                          |GPIO_PIN_15|GPIO_PIN_4|GPIO_PIN_5;
  GPIO_InitStruct.Mode = GPIO_MODE_OUTPUT_PP;
  GPIO_InitStruct.Pull = GPIO_NOPULL;
  GPIO_InitStruct.Speed = GPIO_SPEED_FREQ_LOW;
  HAL_GPIO_Init(GPIOB, &GPIO_InitStruct);

  /*Configure GPIO pins : PD10 PD11 PD14 PD15
                           PD2 */
  GPIO_InitStruct.Pin = GPIO_PIN_10|GPIO_PIN_11|GPIO_PIN_14|GPIO_PIN_15
                          |GPIO_PIN_2;
  GPIO_InitStruct.Mode = GPIO_MODE_IT_RISING;
  GPIO_InitStruct.Pull = GPIO_NOPULL;
  HAL_GPIO_Init(GPIOD, &GPIO_InitStruct);

  /*Configure GPIO pins : PD12 PD13 PD0 PD7 */
  GPIO_InitStruct.Pin = GPIO_PIN_12|GPIO_PIN_13|GPIO_PIN_0|GPIO_PIN_7;
  GPIO_InitStruct.Mode = GPIO_MODE_OUTPUT_PP;
  GPIO_InitStruct.Pull = GPIO_NOPULL;
  GPIO_InitStruct.Speed = GPIO_SPEED_FREQ_LOW;
  HAL_GPIO_Init(GPIOD, &GPIO_InitStruct);

  /*Configure GPIO pins : PC6 PC9 */
  GPIO_InitStruct.Pin = GPIO_PIN_6|GPIO_PIN_9;
  GPIO_InitStruct.Mode = GPIO_MODE_OUTPUT_PP;
  GPIO_InitStruct.Pull = GPIO_NOPULL;
  GPIO_InitStruct.Speed = GPIO_SPEED_FREQ_LOW;
  HAL_GPIO_Init(GPIOC, &GPIO_InitStruct);

  /*Configure GPIO pins : PC10 PC11 PC12 */
  GPIO_InitStruct.Pin = GPIO_PIN_10|GPIO_PIN_11|GPIO_PIN_12;
  GPIO_InitStruct.Mode = GPIO_MODE_AF_PP;
  GPIO_InitStruct.Pull = GPIO_NOPULL;
  GPIO_InitStruct.Speed = GPIO_SPEED_FREQ_VERY_HIGH;
  GPIO_InitStruct.Alternate = GPIO_AF6_SPI3;
  HAL_GPIO_Init(GPIOC, &GPIO_InitStruct);

  /*Configure GPIO pin : PD1 */
  GPIO_InitStruct.Pin = GPIO_PIN_1;
  GPIO_InitStruct.Mode = GPIO_MODE_AF_PP;
  GPIO_InitStruct.Pull = GPIO_NOPULL;
  GPIO_InitStruct.Speed = GPIO_SPEED_FREQ_VERY_HIGH;
  GPIO_InitStruct.Alternate = GPIO_AF5_SPI2;
  HAL_GPIO_Init(GPIOD, &GPIO_InitStruct);

  /*Configure GPIO pins : PD3 PD4 PD5 PD6 */
  GPIO_InitStruct.Pin = GPIO_PIN_3|GPIO_PIN_4|GPIO_PIN_5|GPIO_PIN_6;
  GPIO_InitStruct.Mode = GPIO_MODE_AF_PP;
  GPIO_InitStruct.Pull = GPIO_NOPULL;
  GPIO_InitStruct.Speed = GPIO_SPEED_FREQ_VERY_HIGH;
  GPIO_InitStruct.Alternate = GPIO_AF7_USART2;
  HAL_GPIO_Init(GPIOD, &GPIO_InitStruct);

  /*Configure GPIO pins : PB8 PB9 */
  GPIO_InitStruct.Pin = GPIO_PIN_8|GPIO_PIN_9;
  GPIO_InitStruct.Mode = GPIO_MODE_AF_OD;
  GPIO_InitStruct.Pull = GPIO_PULLUP;
  GPIO_InitStruct.Speed = GPIO_SPEED_FREQ_VERY_HIGH;
  GPIO_InitStruct.Alternate = GPIO_AF4_I2C1;
  HAL_GPIO_Init(GPIOB, &GPIO_InitStruct);

  /* EXTI interrupt init*/
  HAL_NVIC_SetPriority(EXTI9_5_IRQn, 5, 0);
  HAL_NVIC_EnableIRQ(EXTI9_5_IRQn);

  HAL_NVIC_SetPriority(EXTI15_10_IRQn, 5, 0);
  HAL_NVIC_EnableIRQ(EXTI15_10_IRQn);

}

void StartDefaultTask(void const * argument)
{

  /* USER CODE BEGIN 5 */
  /* Infinite loop */
	HAL_SPI_Receive_IT(&hspi1, spi_data_rx, SPI_DATA_RX_SIZE);
	SEGGER_RTT_printf(0, "SPI waiting\n");
  for(;;)
  {
    osDelay(1);
  }
  /* USER CODE END 5 */
}

void HAL_TIM_PeriodElapsedCallback(TIM_HandleTypeDef *htim)
{
  if (htim->Instance == TIM1) {
    HAL_IncTick();
  }
}

void Error_Handler(void)
{
}

/************************ (C) COPYRIGHT STMicroelectronics *****END OF FILE****/
